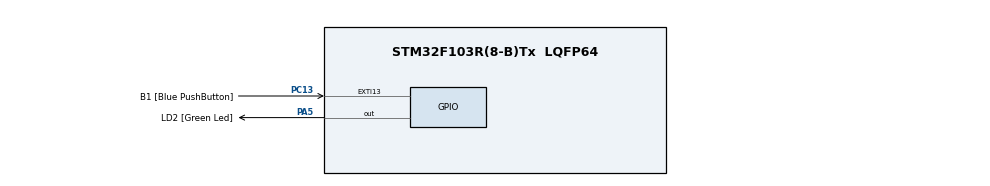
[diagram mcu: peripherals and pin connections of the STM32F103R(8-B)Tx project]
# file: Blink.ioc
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Mcu.Family=STM32F1
Mcu.Name=STM32F103R(8-B)Tx
Mcu.Package=LQFP64
NVIC.PriorityGroup=NVIC_PRIORITYGROUP_4
PA13.GPIO_Label=TMS
PA13.Mode=Serial_Wire
PA13.Signal=SYS_JTMS-SWDIO
PA14.GPIO_Label=TCK
PA14.Mode=Serial_Wire
PA14.Signal=SYS_JTCK-SWCLK
PA5.GPIO_Label=LD2 [Green Led]
PA5.GPIO_ModeDefaultOutputPP=GPIO_MODE_OUTPUT_PP
PA5.GPIO_PuPd=GPIO_NOPULL
PA5.GPIO_Speed=GPIO_SPEED_FREQ_LOW
PA5.Signal=GPIO_Output
PB3.GPIO_Label=SWO
PB3.Signal=SYS_JTDO-TRACESWO
PC13-TAMPER-RTC.GPIO_Label=B1 [Blue PushButton]
PC13-TAMPER-RTC.GPIO_PuPd=GPIO_NOPULL
PC13-TAMPER-RTC.Signal=GPXTI13
PC14-OSC32_IN.Mode=LSE-External-Oscillator
PC14-OSC32_IN.Signal=RCC_OSC32_IN
PC15-OSC32_OUT.Mode=LSE-External-Oscillator
PC15-OSC32_OUT.Signal=RCC_OSC32_OUT
PD0-OSC_IN.Mode=HSE-External-Clock-Source
PD0-OSC_IN.Signal=RCC_OSC_IN
PD1-OSC_OUT.Mode=HSE-External-Clock-Source
PD1-OSC_OUT.Signal=RCC_OSC_OUT
ProjectManager.HeapSize=0x200
ProjectManager.StackSize=0x400
ProjectManager.TargetToolchain=STM32CubeIDE
RCC.AHBFreq_Value=64000000
RCC.APB1CLKDivider=RCC_HCLK_DIV2
RCC.APB1Freq_Value=32000000
RCC.APB1TimFreq_Value=64000000
RCC.APB2Freq_Value=64000000
RCC.APB2TimFreq_Value=64000000
RCC.HCLKFreq_Value=64000000
RCC.PLLMUL=RCC_PLL_MUL8
RCC.PLLSourceVirtual=RCC_PLLSOURCE_HSE
RCC.RTCClockSelection=RCC_RTCCLKSOURCE_LSE
RCC.SYSCLKFreq_VALUE=64000000
RCC.SYSCLKSource=RCC_SYSCLKSOURCE_PLLCLK
RCC.USBFreq_Value=64000000
board=NUCLEO-F103RB

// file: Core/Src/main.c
/* USER CODE BEGIN Header */
/**
 ******************************************************************************
 * @file           : main.c
 * @brief          : Main program body
 ******************************************************************************
 * @attention
 *
 * Copyright (c) 2026 STMicroelectronics.
 * All rights reserved.
 *
 * This software is licensed under terms that can be found in the LICENSE file
 * in the root directory of this software component.
 * If no LICENSE file comes with this software, it is provided AS-IS.
 *
 ******************************************************************************
 */
/* USER CODE END Header */
#include "main.h"

/* USER CODE BEGIN Includes */
#include "stm32f1xx_ll_rcc.h"
#include "stm32f1xx_ll_bus.h"
#include "stm32f1xx_ll_system.h"
#include "stm32f1xx_ll_exti.h"
#include "stm32f1xx_ll_gpio.h"
#include "stm32f1xx_ll_utils.h"
#include "stm32f1xx_ll_pwr.h"
/* USER CODE END Includes */

void SystemClock_Config(void);
static void MX_GPIO_Init(void);

int main(void)
{

  /* MCU Configuration--------------------------------------------------------*/

  /* Reset of all peripherals, Initializes the Flash interface and the Systick. */
  LL_APB2_GRP1_EnableClock(LL_APB2_GRP1_PERIPH_AFIO);
  LL_APB1_GRP1_EnableClock(LL_APB1_GRP1_PERIPH_PWR);

  /* System interrupt init*/
  NVIC_SetPriorityGrouping(NVIC_PRIORITYGROUP_4);

  /** NOJTAG: JTAG-DP Disabled and SW-DP Enabled
  */
  LL_GPIO_AF_Remap_SWJ_NOJTAG();

  /* Configure the system clock */
  SystemClock_Config();

  /* Initialize all configured peripherals */
  MX_GPIO_Init();

  /* Infinite loop */
	while (1) {

    /* USER CODE BEGIN 3 */
    LL_GPIO_TogglePin(LD2_GPIO_Port, LD2_Pin);
    LL_mDelay(1000);
	}
  /* USER CODE END 3 */
}

void SystemClock_Config(void)
{
  LL_FLASH_SetLatency(LL_FLASH_LATENCY_2);
  while(LL_FLASH_GetLatency()!= LL_FLASH_LATENCY_2)
  {
  }
  LL_RCC_HSE_EnableBypass();
  LL_RCC_HSE_Enable();

   /* Wait till HSE is ready */
  while(LL_RCC_HSE_IsReady() != 1)
  {

  }
  LL_RCC_PLL_ConfigDomain_SYS(LL_RCC_PLLSOURCE_HSE_DIV_1, LL_RCC_PLL_MUL_8);
  LL_RCC_PLL_Enable();

   /* Wait till PLL is ready */
  while(LL_RCC_PLL_IsReady() != 1)
  {

  }
  LL_RCC_SetAHBPrescaler(LL_RCC_SYSCLK_DIV_1);
  LL_RCC_SetAPB1Prescaler(LL_RCC_APB1_DIV_2);
  LL_RCC_SetAPB2Prescaler(LL_RCC_APB2_DIV_1);
  LL_RCC_SetSysClkSource(LL_RCC_SYS_CLKSOURCE_PLL);

   /* Wait till System clock is ready */
  while(LL_RCC_GetSysClkSource() != LL_RCC_SYS_CLKSOURCE_STATUS_PLL)
  {

  }
  LL_Init1msTick(64000000);
  LL_SetSystemCoreClock(64000000);
}

static void MX_GPIO_Init(void)
{
  LL_GPIO_InitTypeDef GPIO_InitStruct = {0};

  /* GPIO Ports Clock Enable */
  LL_APB2_GRP1_EnableClock(LL_APB2_GRP1_PERIPH_GPIOA);

  /* Configure LD2 (PA5) as push-pull output */
  LL_GPIO_ResetOutputPin(LD2_GPIO_Port, LD2_Pin);

  GPIO_InitStruct.Pin = LD2_Pin;
  GPIO_InitStruct.Mode = LL_GPIO_MODE_OUTPUT;
  GPIO_InitStruct.Speed = LL_GPIO_SPEED_FREQ_LOW;
  GPIO_InitStruct.OutputType = LL_GPIO_OUTPUT_PUSHPULL;
  LL_GPIO_Init(LD2_GPIO_Port, &GPIO_InitStruct);

}

void Error_Handler(void)
{
	__disable_irq();
	while (1) {
	}
}
